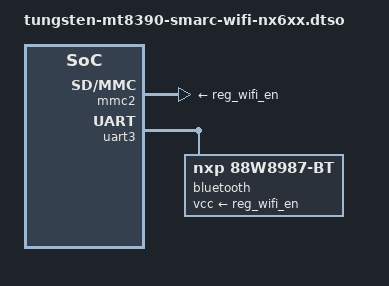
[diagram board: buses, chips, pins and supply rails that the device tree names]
// SPDX-License-Identifier: (GPL-2.0+ OR MIT)
/*
 * On-board SDIO NX6xx module
 */

/dts-v1/;
/plugin/;

&reg_wifi_en {
	startup-delay-us = <20000>;
	off-on-delay-us = <100>;
};

&mmc2 {
	status = "okay";
	vmmc-supply = <&reg_wifi_en>;
};

&uart3 {
	status = "okay";

	bluetooth {
		compatible = "nxp,88w8987-bt";
		fw-init-baudrate = <3000000>;
		vcc-supply = <&reg_wifi_en>;
	};
};
